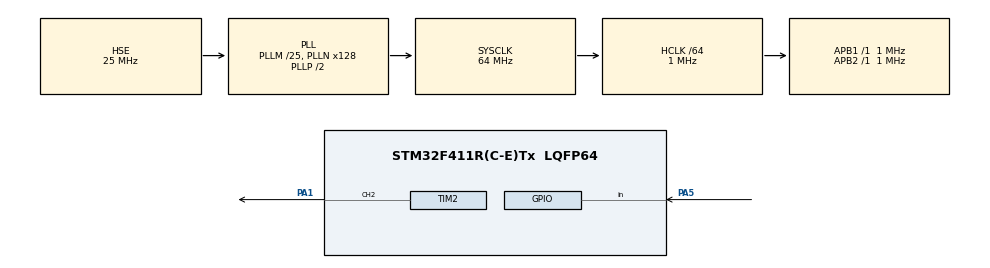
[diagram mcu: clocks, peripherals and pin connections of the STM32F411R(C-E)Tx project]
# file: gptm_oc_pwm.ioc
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Mcu.Family=STM32F4
Mcu.Name=STM32F411R(C-E)Tx
Mcu.Package=LQFP64
NVIC.PriorityGroup=NVIC_PRIORITYGROUP_4
PA1.Signal=S_TIM2_CH2
PA5.Signal=GPIO_Input
PH0\ -\ OSC_IN.Mode=HSE-External-Clock-Source
PH0\ -\ OSC_IN.Signal=RCC_OSC_IN
PH1\ -\ OSC_OUT.Mode=HSE-External-Clock-Source
PH1\ -\ OSC_OUT.Signal=RCC_OSC_OUT
ProjectManager.HeapSize=0x200
ProjectManager.StackSize=0x400
ProjectManager.TargetToolchain=STM32CubeIDE
RCC.48MHZClocksFreq_Value=32000000
RCC.AHBCLKDivider=RCC_SYSCLK_DIV64
RCC.AHBFreq_Value=1000000
RCC.APB1Freq_Value=1000000
RCC.APB1TimFreq_Value=1000000
RCC.APB2Freq_Value=1000000
RCC.APB2TimFreq_Value=1000000
RCC.CortexFreq_Value=1000000
RCC.HCLKFreq_Value=1000000
RCC.HSE_VALUE=25000000
RCC.HSI_VALUE=16000000
RCC.LSE_VALUE=32768
RCC.PLLM=25
RCC.PLLN=128
RCC.PLLSourceVirtual=RCC_PLLSOURCE_HSE
RCC.SYSCLKFreq_VALUE=64000000
RCC.SYSCLKSource=RCC_SYSCLKSOURCE_PLLCLK
RCC.VCOOutputFreq_Value=128000000
SH.S_TIM2_CH2.0=TIM2_CH2,PWM Generation2 CH2
TIM2.Channel-PWM\ Generation2\ CH2=TIM_CHANNEL_2
TIM2.Period=999
TIM2.Prescaler=0
TIM2.Pulse-PWM\ Generation2\ CH2=0
VP_TIM2_VS_ClockSourceINT.Mode=Internal
board=custom

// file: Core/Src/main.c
/* USER CODE BEGIN Header */
/**
 ******************************************************************************
 * @file           : main.c
 * @brief          : Main program body
 ******************************************************************************
 * @attention
 *
 * <h2><center>&copy; Copyright (c) 2021 STMicroelectronics.
 * All rights reserved.</center></h2>
 *
 * This software component is licensed by ST under BSD 3-Clause license,
 * the "License"; You may not use this file except in compliance with the
 * License. You may obtain a copy of the License at:
 *                        opensource.org/licenses/BSD-3-Clause
 *
 ******************************************************************************
 */
/* USER CODE END Header */

#include "main.h"

TIM_HandleTypeDef htim2;

void SystemClock_Config(void);
static void MX_GPIO_Init(void);
static void MX_TIM2_Init(void);

int main(void)
{
  /* USER CODE BEGIN 1 */
	uint16_t val = 0;
  /* USER CODE END 1 */

  /* MCU Configuration--------------------------------------------------------*/

  /* Reset of all peripherals, Initializes the Flash interface and the Systick. */
  HAL_Init();

  /* Configure the system clock */
  SystemClock_Config();

  /* Initialize all configured peripherals */
  MX_GPIO_Init();
  MX_TIM2_Init();
  /* USER CODE BEGIN 2 */
	HAL_TIM_PWM_Start(&htim2, TIM_CHANNEL_2);
  /* USER CODE END 2 */

  /* Infinite loop */
	while (1) {

    /* USER CODE BEGIN 3 */
		while(val < htim2.Init.Period) {
			val+=10;
			__HAL_TIM_SET_COMPARE(&htim2, TIM_CHANNEL_2, val);
			HAL_Delay(1);
		}
		while(val > 0) {
			val-=10;
			__HAL_TIM_SET_COMPARE(&htim2, TIM_CHANNEL_2, val);
			HAL_Delay(1);
		}
	}
  /* USER CODE END 3 */
}

void SystemClock_Config(void)
{
  RCC_OscInitTypeDef RCC_OscInitStruct = {0};
  RCC_ClkInitTypeDef RCC_ClkInitStruct = {0};

  /** Configure the main internal regulator output voltage
  */
  __HAL_RCC_PWR_CLK_ENABLE();
  __HAL_PWR_VOLTAGESCALING_CONFIG(PWR_REGULATOR_VOLTAGE_SCALE1);
  /** Initializes the CPU, AHB and APB busses clocks
  */
  RCC_OscInitStruct.OscillatorType = RCC_OSCILLATORTYPE_HSE;
  RCC_OscInitStruct.HSEState = RCC_HSE_BYPASS;
  RCC_OscInitStruct.PLL.PLLState = RCC_PLL_ON;
  RCC_OscInitStruct.PLL.PLLSource = RCC_PLLSOURCE_HSE;
  RCC_OscInitStruct.PLL.PLLM = 25;
  RCC_OscInitStruct.PLL.PLLN = 128;
  RCC_OscInitStruct.PLL.PLLP = RCC_PLLP_DIV2;
  RCC_OscInitStruct.PLL.PLLQ = 4;
  if (HAL_RCC_OscConfig(&RCC_OscInitStruct) != HAL_OK)
  {
    Error_Handler();
  }
  /** Initializes the CPU, AHB and APB busses clocks
  */
  RCC_ClkInitStruct.ClockType = RCC_CLOCKTYPE_HCLK|RCC_CLOCKTYPE_SYSCLK
                              |RCC_CLOCKTYPE_PCLK1|RCC_CLOCKTYPE_PCLK2;
  RCC_ClkInitStruct.SYSCLKSource = RCC_SYSCLKSOURCE_PLLCLK;
  RCC_ClkInitStruct.AHBCLKDivider = RCC_SYSCLK_DIV64;
  RCC_ClkInitStruct.APB1CLKDivider = RCC_HCLK_DIV1;
  RCC_ClkInitStruct.APB2CLKDivider = RCC_HCLK_DIV1;

  if (HAL_RCC_ClockConfig(&RCC_ClkInitStruct, FLASH_LATENCY_0) != HAL_OK)
  {
    Error_Handler();
  }
}

static void MX_TIM2_Init(void)
{

  TIM_ClockConfigTypeDef sClockSourceConfig = {0};
  TIM_MasterConfigTypeDef sMasterConfig = {0};
  TIM_OC_InitTypeDef sConfigOC = {0};

  htim2.Instance = TIM2;
  htim2.Init.Prescaler = 0;
  htim2.Init.CounterMode = TIM_COUNTERMODE_UP;
  htim2.Init.Period = 999;
  htim2.Init.ClockDivision = TIM_CLOCKDIVISION_DIV1;
  htim2.Init.AutoReloadPreload = TIM_AUTORELOAD_PRELOAD_DISABLE;
  if (HAL_TIM_Base_Init(&htim2) != HAL_OK)
  {
    Error_Handler();
  }
  sClockSourceConfig.ClockSource = TIM_CLOCKSOURCE_INTERNAL;
  if (HAL_TIM_ConfigClockSource(&htim2, &sClockSourceConfig) != HAL_OK)
  {
    Error_Handler();
  }
  if (HAL_TIM_PWM_Init(&htim2) != HAL_OK)
  {
    Error_Handler();
  }
  sMasterConfig.MasterOutputTrigger = TIM_TRGO_RESET;
  sMasterConfig.MasterSlaveMode = TIM_MASTERSLAVEMODE_DISABLE;
  if (HAL_TIMEx_MasterConfigSynchronization(&htim2, &sMasterConfig) != HAL_OK)
  {
    Error_Handler();
  }
  sConfigOC.OCMode = TIM_OCMODE_PWM1;
  sConfigOC.Pulse = 0;
  sConfigOC.OCPolarity = TIM_OCPOLARITY_HIGH;
  sConfigOC.OCFastMode = TIM_OCFAST_DISABLE;
  if (HAL_TIM_PWM_ConfigChannel(&htim2, &sConfigOC, TIM_CHANNEL_2) != HAL_OK)
  {
    Error_Handler();
  }
  HAL_TIM_MspPostInit(&htim2);

}

static void MX_GPIO_Init(void)
{
  GPIO_InitTypeDef GPIO_InitStruct = {0};

  /* GPIO Ports Clock Enable */
  __HAL_RCC_GPIOH_CLK_ENABLE();
  __HAL_RCC_GPIOA_CLK_ENABLE();

  /*Configure GPIO pin : PA5 */
  GPIO_InitStruct.Pin = GPIO_PIN_5;
  GPIO_InitStruct.Mode = GPIO_MODE_INPUT;
  GPIO_InitStruct.Pull = GPIO_NOPULL;
  HAL_GPIO_Init(GPIOA, &GPIO_InitStruct);

}

void Error_Handler(void)
{
}

/************************ (C) COPYRIGHT STMicroelectronics *****END OF FILE****/
